VERSION "1.0"

NS_ :

BS_:

BU_: ECU1_VCU ECU2_Pedal ECU3_Body JETSON_GW

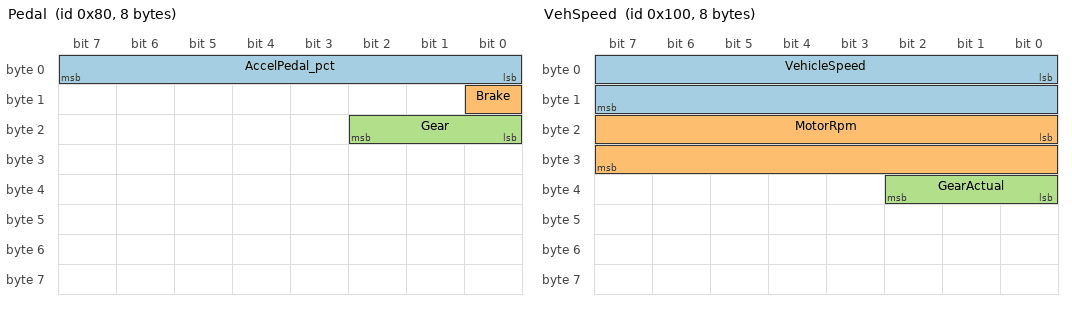
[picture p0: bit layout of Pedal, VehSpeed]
BO_ 128 Pedal: 8 ECU2_Pedal
 SG_ AccelPedal_pct : 0|8@1+ (0.5,0) [0|100] "%" ECU1_VCU,JETSON_GW
 SG_ Brake : 8|1@1+ (1,0) [0|1] "" ECU1_VCU,ECU3_Body,JETSON_GW
 SG_ Gear : 16|3@1+ (1,0) [0|7] "" ECU1_VCU,JETSON_GW

BO_ 256 VehSpeed: 8 ECU1_VCU
 SG_ VehicleSpeed : 0|16@1+ (0.01,0) [0|250] "km/h" ECU3_Body,JETSON_GW
 SG_ MotorRpm : 16|16@1- (1,0) [-12000|12000] "rpm" JETSON_GW
 SG_ GearActual : 32|3@1+ (1,0) [0|7] "" JETSON_GW

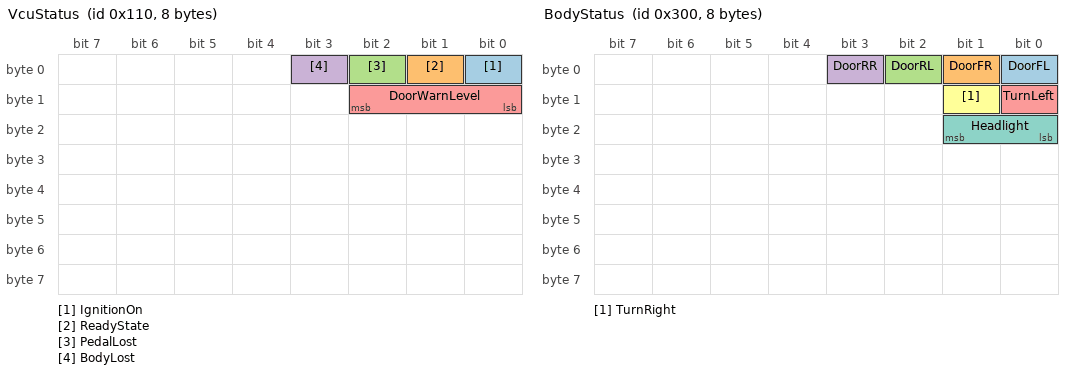
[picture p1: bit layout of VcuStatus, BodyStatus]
BO_ 272 VcuStatus: 8 ECU1_VCU
 SG_ IgnitionOn : 0|1@1+ (1,0) [0|1] "" JETSON_GW
 SG_ ReadyState : 1|1@1+ (1,0) [0|1] "" JETSON_GW
 SG_ PedalLost : 2|1@1+ (1,0) [0|1] "" JETSON_GW
 SG_ BodyLost : 3|1@1+ (1,0) [0|1] "" JETSON_GW
 SG_ DoorWarnLevel : 8|3@1+ (1,0) [0|7] "" JETSON_GW

BO_ 768 BodyStatus: 8 ECU3_Body
 SG_ DoorFL : 0|1@1+ (1,0) [0|1] "" ECU1_VCU,JETSON_GW
 SG_ DoorFR : 1|1@1+ (1,0) [0|1] "" ECU1_VCU,JETSON_GW
 SG_ DoorRL : 2|1@1+ (1,0) [0|1] "" ECU1_VCU,JETSON_GW
 SG_ DoorRR : 3|1@1+ (1,0) [0|1] "" ECU1_VCU,JETSON_GW
 SG_ TurnLeft : 8|1@1+ (1,0) [0|1] "" JETSON_GW
 SG_ TurnRight : 9|1@1+ (1,0) [0|1] "" JETSON_GW
 SG_ Headlight : 16|2@1+ (1,0) [0|3] "" JETSON_GW

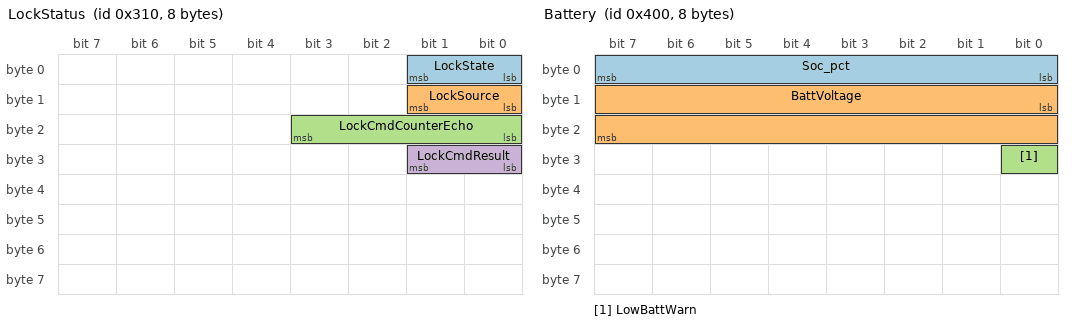
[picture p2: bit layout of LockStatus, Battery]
BO_ 784 LockStatus: 8 ECU3_Body
 SG_ LockState : 0|2@1+ (1,0) [0|3] "" JETSON_GW
 SG_ LockSource : 8|2@1+ (1,0) [0|3] "" JETSON_GW
 SG_ LockCmdCounterEcho : 16|4@1+ (1,0) [0|15] "" JETSON_GW
 SG_ LockCmdResult : 24|2@1+ (1,0) [0|3] "" JETSON_GW

BO_ 1024 Battery: 8 ECU1_VCU
 SG_ Soc_pct : 0|8@1+ (0.5,0) [0|100] "%" JETSON_GW
 SG_ BattVoltage : 8|16@1+ (0.1,0) [0|500] "V" JETSON_GW
 SG_ LowBattWarn : 24|1@1+ (1,0) [0|1] "" JETSON_GW

BO_ 1280 LockCommand: 8 JETSON_GW
 SG_ LockReq : 0|2@1+ (1,0) [0|3] "" ECU3_Body
 SG_ LockCmdCounter : 8|4@1+ (1,0) [0|15] "" ECU3_Body

CM_ "Mang CAN mo phong o to tren ban (DAKS). Phien ban 1.0 (chot 30/10/2026); moi thay doi sau phai tang phien ban va bao DACN. CAN thuong 500 kbit/s, ID 11 bit. Quy uoc chung: moi message dai 8 byte (du cho de them tin hieu ma khong doi DLC); byte order Intel (little endian); quy uoc SNA (khong co du lieu): tin hieu khong dau = toan bit 1 (0xFF voi 8 bit, 0xFFFF voi 16 bit); tin hieu co dau = gia tri nho nhat (0x8000 voi 16 bit); tin hieu 1 bit khong co SNA, mat du lieu phat hien bang timeout. Dai ID: 0x080-0x1FF truyen dong + khung gam, 0x300-0x3FF than xe, 0x400-0x4FF pin, 0x500-0x5FF HMI -> ECU (lenh tu app qua Jetson), 0x700-0x7FF chan doan UDS.";
CM_ BU_ ECU1_VCU "VCU: board Hiwonder ROS Robot Controller (STM32F407VET6) chay Trampoline OSEK. Chua mo hinh xe va mo hinh pin (tinh toan, khong do), dat o mot dau bus (tro 120 ohm R23 co san tren board). Khoa dien = cong tac so 1 (PD3); READY = khoa dien ON + Brake + nut K1. Canh bao cua bang buzzer PA8 va LED roi PE2 theo DoorWarnLevel (nguong 3 km/h, vung tre 2-3 km/h). Bao trang thai qua VcuStatus 0x110.";
CM_ BU_ ECU2_Pedal "Pedal: STM32F103C8T6 + SN65HVD230. Bien tro = chan ga, nut = phanh, cong tac = so P/R/N/D.";
CM_ BU_ ECU3_Body "Body: STM32F103C8T6 + SN65HVD230. Cong tac cua, can xi-nhan, den pha; dieu khien 4 LED roi: xi-nhan trai, xi-nhan phai, phanh, khoa (co cau khoa mo phong bang LED; servo SG90 de phan mo rong). La ben quyet dinh cuoi cung ve khoa, theo huong an toan = mo duoc: chi tu choi lenh MO tu app khi VehicleSpeed > 15 km/h; nut tren ECU3 luon mo duoc; tu khoa mot lan khi VehicleSpeed vuot len tren 15 km/h, chi tu khoa lai sau khi xuong duoi 10 km/h; mat VehSpeed thi khong tu khoa va khong chan mo.";
CM_ BU_ JETSON_GW "Jetson Orin Nano: gateway/cockpit. Giai ma bus theo DBC nay roi gui sang Android theo TEN tin hieu. Chieu nguoc lai: nhan lenh tu app va gui len bus. Gateway CHI duoc gui ID trong dai 0x500-0x5FF; moi ID khac bi chan.";
CM_ BO_ 128 "Trang thai ban dap va can so. Gui moi 20 ms. Byte 6-7 de trong, du phong cho E2E (counter + CRC) neu chon phan mo rong E2E.";
CM_ SG_ 128 AccelPedal_pct "Do dap chan ga. Buoc 0.5 % (201 muc cho 0-100 %, du min so voi bien tro qua ADC 12 bit). Tho 255 = SNA khi ADC ra ngoai 5-95 % thang do (dut day bien tro; mach co 2 tro noi tiep + 1 tro keo xuong o chan ADC).";
CM_ SG_ 128 Brake "Nut phanh: 1 = dang dap. ECU3 dung tin hieu nay de bat LED phanh.";
CM_ SG_ 128 Gear "So nguoi lai YEU CAU (vi tri can so). 3 bit, du cho 4 so + du phong; 7 = SNA. So xe thuc su cai la GearActual trong VehSpeed. Doc on dinh >= 20 ms moi doi; khong chan nao hoac hai chan cung luc thi 7 = SNA.";
CM_ BO_ 256 "Trang thai chuyen dong tu mo hinh xe trong VCU. Gui moi 20 ms.";
CM_ SG_ 256 VehicleSpeed "Toc do xe (do lon, khong dau). Buoc 0.01 km/h, 16 bit toi 655.34 km/h; mo hinh gioi han 250. Chieu chay suy tu Gear. Tho 0xFFFF = SNA.";
CM_ SG_ 256 MotorRpm "Vong quay mo-to, CO DAU: am khi lui (so R). 16 bit co dau, buoc 1 rpm. Gia su mo-to toi da 12000 rpm (co the chinh theo mo hinh). Tho 0x8000 = SNA.";
CM_ SG_ 256 GearActual "So VCU THUC SU cai, tach khoi so nguoi lai yeu cau (Gear trong Pedal). VCU co the khong doi so, vi du khong vao R khi xe dang tien. Cung bang ma voi Gear; 7 = SNA.";
CM_ BO_ 272 "Trang thai VCU de app hien thi lai (tang 3). Gui moi 100 ms.";
CM_ SG_ 272 IgnitionOn "Khoa dien: 1 = ON (cong tac so 1 tren board, PD3 = 0 on dinh >= 50 ms).";
CM_ SG_ 272 ReadyState "1 = READY. Vao khi khoa dien ON + Brake = 1 + bam K1; ra khi khoa dien OFF hoac bam K1 luc VehicleSpeed < 1 km/h. Chua READY thi ga khong co tac dung.";
CM_ SG_ 272 PedalLost "1 = mat Pedal qua 100 ms. VCU coi ga = 0.";
CM_ SG_ 272 BodyLost "1 = mat BodyStatus qua 500 ms.";
CM_ SG_ 272 DoorWarnLevel "Muc canh bao cua VCU dang phat: 0 tat; 1 nhac nhe (cua mo, khoa dien ON, toc do <= 3 km/h: LED PE2 sang lien); 2 canh bao (cua mo va toc do > 3 km/h, tat khi < 2 km/h: buzzer PA8 + LED PE2 nhay 2 Hz); 3 khong biet trang thai cua (mat ECU3: LED nhay 0.5 Hz, buzzer im); 7 SNA.";
CM_ BO_ 768 "Trang thai than xe. Gui moi 100 ms VA gui ngay khi co tin hieu doi (khong nhanh hon GenMsgDelayTime).";
CM_ SG_ 768 DoorFL "Cua truoc trai: 1 = mo. Ban cung dau tien chi co 1 cong tac cua noi vao DoorFL; 3 cua con lai gui 0 (dong).";
CM_ SG_ 768 TurnLeft "Can xi-nhan gat sang trai (1 = dang bat). Day la trang thai CAN GAT, khong phai trang thai den dang sang: ECU3 tu nhay LED, HMI tu nhay bieu tuong.";
CM_ SG_ 768 TurnRight "Can xi-nhan gat sang phai (1 = dang bat). Xem ghi chu TurnLeft.";
CM_ SG_ 768 Headlight "Den pha. 2 bit: 0 tat, 1 cos, 2 pha, 3 SNA. Ban cung dau chi co cong tac bat/tat (0/1); muc 2 de danh.";
CM_ BO_ 784 "Trang thai khoa cua trung tam tu ECU3. Gui moi 100 ms VA gui ngay khi trang thai doi (khong nhanh hon GenMsgDelayTime).";
CM_ SG_ 784 LockState "Trang thai khoa: 0 mo, 1 khoa, 2 loi (de danh; ban co cau LED chua phat hien duoc loi nen khong dung), 3 SNA.";
CM_ SG_ 784 LockSource "Nguon cua lan doi trang thai gan nhat: 0 app, 1 tu khoa theo toc do, 2 nut tren ECU3, 3 SNA.";
CM_ SG_ 784 LockCmdCounterEcho "Tra lai LockCmdCounter cua lenh gan nhat ECU3 da xu ly (ke ca lenh bi tu choi). App dung de do vong lenh; qua 500 ms ke tu luc gui lenh ma chua thay echo trung thi bao khoa khong phan hoi. 15 = SNA (chua xu ly lenh nao).";
CM_ SG_ 784 LockCmdResult "Ket qua xu ly lenh co bo dem bang LockCmdCounterEcho: 0 Done (da thuc hien), 1 Rejected (ECU3 tu choi, vi du lenh mo khi VehicleSpeed > 15 km/h), 2 AlreadyInState (da o dung trang thai yeu cau), 3 SNA.";
CM_ BO_ 1024 "Trang thai pin tu mo hinh trong VCU. Gui moi 500 ms (pin thay doi cham).";
CM_ SG_ 1024 Soc_pct "Muc pin con lai. Buoc 0.5 %. Tho 255 = SNA.";
CM_ SG_ 1024 BattVoltage "Dien ap bo pin mo phong. Buoc 0.1 V, 16 bit. Gia su bo pin xe dien khoang 350-400 V (so mo phong, khong phai pin that). Tho 0xFFFF = SNA.";
CM_ SG_ 1024 LowBattWarn "Canh bao pin yeu: 1 = Soc duoi nguong (nguong dat trong VCU, du kien 20 %).";
CM_ BO_ 1280 "Lenh khoa/mo cua tu app, Jetson dich sang CAN. Chi gui theo su kien (moi lan bam), khong gui theo chu ky nen khong co timeout. ECU3 quyet dinh co thuc hien hay khong va bao lai qua LockStatus.";
CM_ SG_ 1280 LockReq "0 khong lam gi, 1 khoa, 2 mo, 3 SNA.";
CM_ SG_ 1280 LockCmdCounter "Tang 1 moi lan bam de ECU3 phan biet hai lan bam lien tiep cung mot lenh. Dem 0-14 roi quay ve 0; 15 = SNA theo quy uoc chung.";

BA_DEF_ "BusType" STRING ;
BA_DEF_ "Baudrate" INT 0 1000000;
BA_DEF_ BO_ "GenMsgCycleTime" INT 0 65535;
BA_DEF_ BO_ "GenMsgSendType" ENUM "Cyclic","CyclicAndOnChange","Event";
BA_DEF_ BO_ "GenMsgDelayTime" INT 0 65535;
BA_DEF_ BO_ "GenMsgTimeoutTime" INT 0 65535;
BA_DEF_DEF_ "BusType" "CAN";
BA_DEF_DEF_ "Baudrate" 500000;
BA_DEF_DEF_ "GenMsgCycleTime" 0;
BA_DEF_DEF_ "GenMsgSendType" "Cyclic";
BA_DEF_DEF_ "GenMsgDelayTime" 0;
BA_DEF_DEF_ "GenMsgTimeoutTime" 0;
BA_ "GenMsgCycleTime" BO_ 128 20;
BA_ "GenMsgTimeoutTime" BO_ 128 100;
BA_ "GenMsgCycleTime" BO_ 256 20;
BA_ "GenMsgTimeoutTime" BO_ 256 100;
BA_ "GenMsgCycleTime" BO_ 272 100;
BA_ "GenMsgTimeoutTime" BO_ 272 500;
BA_ "GenMsgCycleTime" BO_ 768 100;
BA_ "GenMsgSendType" BO_ 768 1;
BA_ "GenMsgDelayTime" BO_ 768 20;
BA_ "GenMsgTimeoutTime" BO_ 768 500;
BA_ "GenMsgCycleTime" BO_ 784 100;
BA_ "GenMsgSendType" BO_ 784 1;
BA_ "GenMsgDelayTime" BO_ 784 20;
BA_ "GenMsgTimeoutTime" BO_ 784 500;
BA_ "GenMsgCycleTime" BO_ 1024 500;
BA_ "GenMsgTimeoutTime" BO_ 1024 2500;
BA_ "GenMsgSendType" BO_ 1280 2;

VAL_ 128 AccelPedal_pct 255 "SNA" ;
VAL_ 128 Gear 7 "SNA" 3 "D" 2 "N" 1 "R" 0 "P" ;
VAL_ 256 VehicleSpeed 65535 "SNA" ;
VAL_ 256 MotorRpm -32768 "SNA" ;
VAL_ 256 GearActual 7 "SNA" 3 "D" 2 "N" 1 "R" 0 "P" ;
VAL_ 272 DoorWarnLevel 7 "SNA" 3 "Unknown" 2 "Warning" 1 "Reminder" 0 "Off" ;
VAL_ 768 Headlight 3 "SNA" 2 "HighBeam" 1 "LowBeam" 0 "Off" ;
VAL_ 784 LockState 3 "SNA" 2 "Fault" 1 "Locked" 0 "Unlocked" ;
VAL_ 784 LockSource 3 "SNA" 2 "Ecu3Button" 1 "AutoSpeed" 0 "App" ;
VAL_ 784 LockCmdCounterEcho 15 "SNA" ;
VAL_ 784 LockCmdResult 3 "SNA" 2 "AlreadyInState" 1 "Rejected" 0 "Done" ;
VAL_ 1024 Soc_pct 255 "SNA" ;
VAL_ 1024 BattVoltage 65535 "SNA" ;
VAL_ 1280 LockReq 3 "SNA" 2 "Unlock" 1 "Lock" 0 "NoAction" ;
VAL_ 1280 LockCmdCounter 15 "SNA" ;

SIG_GROUP_ 128 PedalGroup 1 : AccelPedal_pct Brake Gear;
